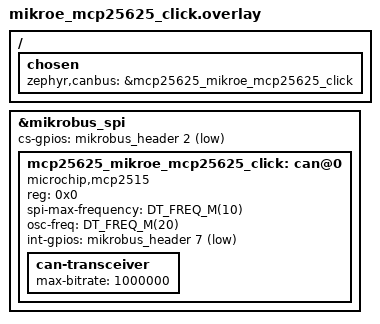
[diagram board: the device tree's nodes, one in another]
/*
 * SPDX-FileCopyrightText: Copyright (c) 2026 Navimatix GmbH
 * SPDX-FileCopyrightText: Copyright (c) 2026 TiaC Systems
 * SPDX-License-Identifier: Apache-2.0
 */

#include <zephyr/dt-bindings/gpio/gpio.h>
#include <freq.h>

/ {
	chosen {
		zephyr,canbus = &mcp25625_mikroe_mcp25625_click;
	};
};

&mikrobus_spi {
	cs-gpios = <&mikrobus_header 2 GPIO_ACTIVE_LOW>;

	mcp25625_mikroe_mcp25625_click: can@0 {
		compatible = "microchip,mcp2515";
		reg = <0x0>;
		spi-max-frequency = <DT_FREQ_M(10)>;
		osc-freq = <DT_FREQ_M(20)>;
		int-gpios = <&mikrobus_header 7 GPIO_ACTIVE_LOW>;
		status = "okay";

		can-transceiver {
			max-bitrate = <1000000>;
		};
	};
};
